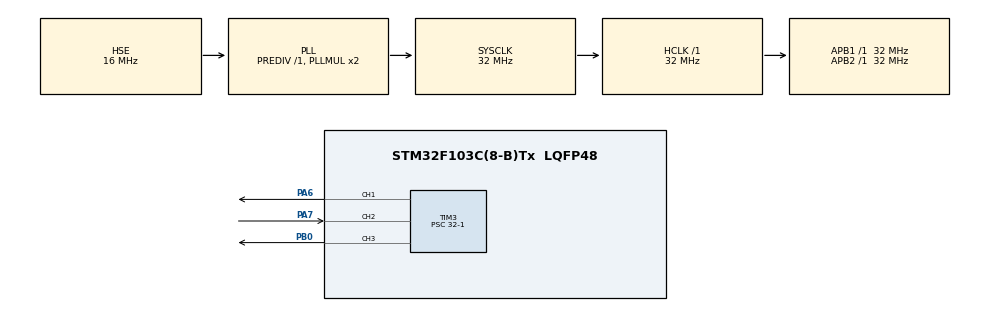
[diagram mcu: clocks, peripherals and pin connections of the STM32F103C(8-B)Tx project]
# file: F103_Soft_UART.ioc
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Mcu.Family=STM32F1
Mcu.Name=STM32F103C(8-B)Tx
Mcu.Package=LQFP48
NVIC.PriorityGroup=NVIC_PRIORITYGROUP_4
NVIC.TIM3_IRQn=true\:0\:0\:false\:false\:true\:true\:true\:true
PA6.GPIO_Speed=GPIO_SPEED_FREQ_HIGH
PA6.Signal=S_TIM3_CH1
PA7.GPIO_PuPd=GPIO_PULLUP
PA7.Signal=S_TIM3_CH2
PB0.Signal=S_TIM3_CH3
PD0-OSC_IN.Mode=HSE-External-Oscillator
PD0-OSC_IN.Signal=RCC_OSC_IN
PD1-OSC_OUT.Mode=HSE-External-Oscillator
PD1-OSC_OUT.Signal=RCC_OSC_OUT
ProjectManager.HeapSize=0x200
ProjectManager.StackSize=0x400
ProjectManager.TargetToolchain=STM32CubeIDE
RCC.AHBFreq_Value=32000000
RCC.APB1Freq_Value=32000000
RCC.APB1TimFreq_Value=32000000
RCC.APB2Freq_Value=32000000
RCC.APB2TimFreq_Value=32000000
RCC.HCLKFreq_Value=32000000
RCC.HSE_VALUE=16000000
RCC.PLLSourceVirtual=RCC_PLLSOURCE_HSE
RCC.SYSCLKFreq_VALUE=32000000
RCC.SYSCLKSource=RCC_SYSCLKSOURCE_PLLCLK
RCC.USBFreq_Value=32000000
SH.S_TIM3_CH1.0=TIM3_CH1,Output Compare1 CH1
SH.S_TIM3_CH2.0=TIM3_CH2,Input_Capture2_from_TI2
SH.S_TIM3_CH3.0=TIM3_CH3,Output Compare3 CH3
TIM3.Channel-Input_Capture2_from_TI2=TIM_CHANNEL_2
TIM3.Channel-Output\ Compare1\ CH1=TIM_CHANNEL_1
TIM3.Channel-Output\ Compare3\ CH3=TIM_CHANNEL_3
TIM3.ICPolarity_CH2=TIM_INPUTCHANNELPOLARITY_FALLING
TIM3.OCMode_1=TIM_OCMODE_FORCED_ACTIVE
TIM3.Prescaler=32-1
VP_TIM3_VS_ClockSourceINT.Mode=Internal
board=custom

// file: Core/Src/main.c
/* USER CODE BEGIN Header */
/**
  ******************************************************************************
  * @file           : main.c
  * @brief          : Main program body
  ******************************************************************************
  * @attention
  *
  * Copyright (c) 2024 STMicroelectronics.
  * All rights reserved.
  *
  * This software is licensed under terms that can be found in the LICENSE file
  * in the root directory of this software component.
  * If no LICENSE file comes with this software, it is provided AS-IS.
  *
  ******************************************************************************
  */
/* USER CODE END Header */
#include "main.h"

/* USER CODE BEGIN Includes */
#include "SoftwareSerial.h"
/* USER CODE END Includes */

TIM_HandleTypeDef htim3;

void SystemClock_Config(void);
static void MX_GPIO_Init(void);
static void MX_TIM3_Init(void);

/* USER CODE BEGIN 0 */
uint32_t check_if;
/* USER CODE END 0 */

int main(void)
{

  /* MCU Configuration--------------------------------------------------------*/

  /* Reset of all peripherals, Initializes the Flash interface and the Systick. */
  HAL_Init();

  /* Configure the system clock */
  SystemClock_Config();

  /* Initialize all configured peripherals */
  MX_GPIO_Init();
  MX_TIM3_Init();
  /* USER CODE BEGIN 2 */
  ssInit(9600); // Initialise software UART and specify the baud rate
  while(1) {
	  if(isRxAvailable()) {
		  ssWriteByte(ssReadByte());
		  check_if++;
	  }
  }

  /* USER CODE END 2 */

  /* Infinite loop */
  while (1)
  {

  }
}

void SystemClock_Config(void)
{
  RCC_OscInitTypeDef RCC_OscInitStruct = {0};
  RCC_ClkInitTypeDef RCC_ClkInitStruct = {0};

  /** Initializes the RCC Oscillators according to the specified parameters
  * in the RCC_OscInitTypeDef structure.
  */
  RCC_OscInitStruct.OscillatorType = RCC_OSCILLATORTYPE_HSE;
  RCC_OscInitStruct.HSEState = RCC_HSE_ON;
  RCC_OscInitStruct.HSEPredivValue = RCC_HSE_PREDIV_DIV1;
  RCC_OscInitStruct.HSIState = RCC_HSI_ON;
  RCC_OscInitStruct.PLL.PLLState = RCC_PLL_ON;
  RCC_OscInitStruct.PLL.PLLSource = RCC_PLLSOURCE_HSE;
  RCC_OscInitStruct.PLL.PLLMUL = RCC_PLL_MUL2;
  if (HAL_RCC_OscConfig(&RCC_OscInitStruct) != HAL_OK)
  {
    Error_Handler();
  }

  /** Initializes the CPU, AHB and APB buses clocks
  */
  RCC_ClkInitStruct.ClockType = RCC_CLOCKTYPE_HCLK|RCC_CLOCKTYPE_SYSCLK
                              |RCC_CLOCKTYPE_PCLK1|RCC_CLOCKTYPE_PCLK2;
  RCC_ClkInitStruct.SYSCLKSource = RCC_SYSCLKSOURCE_PLLCLK;
  RCC_ClkInitStruct.AHBCLKDivider = RCC_SYSCLK_DIV1;
  RCC_ClkInitStruct.APB1CLKDivider = RCC_HCLK_DIV1;
  RCC_ClkInitStruct.APB2CLKDivider = RCC_HCLK_DIV1;

  if (HAL_RCC_ClockConfig(&RCC_ClkInitStruct, FLASH_LATENCY_1) != HAL_OK)
  {
    Error_Handler();
  }
}

static void MX_TIM3_Init(void)
{

  TIM_ClockConfigTypeDef sClockSourceConfig = {0};
  TIM_MasterConfigTypeDef sMasterConfig = {0};
  TIM_OC_InitTypeDef sConfigOC = {0};
  TIM_IC_InitTypeDef sConfigIC = {0};

  htim3.Instance = TIM3;
  htim3.Init.Prescaler = 32-1;
  htim3.Init.CounterMode = TIM_COUNTERMODE_UP;
  htim3.Init.Period = 65535;
  htim3.Init.ClockDivision = TIM_CLOCKDIVISION_DIV1;
  htim3.Init.AutoReloadPreload = TIM_AUTORELOAD_PRELOAD_DISABLE;
  if (HAL_TIM_Base_Init(&htim3) != HAL_OK)
  {
    Error_Handler();
  }
  sClockSourceConfig.ClockSource = TIM_CLOCKSOURCE_INTERNAL;
  if (HAL_TIM_ConfigClockSource(&htim3, &sClockSourceConfig) != HAL_OK)
  {
    Error_Handler();
  }
  if (HAL_TIM_OC_Init(&htim3) != HAL_OK)
  {
    Error_Handler();
  }
  if (HAL_TIM_IC_Init(&htim3) != HAL_OK)
  {
    Error_Handler();
  }
  sMasterConfig.MasterOutputTrigger = TIM_TRGO_RESET;
  sMasterConfig.MasterSlaveMode = TIM_MASTERSLAVEMODE_DISABLE;
  if (HAL_TIMEx_MasterConfigSynchronization(&htim3, &sMasterConfig) != HAL_OK)
  {
    Error_Handler();
  }
  sConfigOC.OCMode = TIM_OCMODE_FORCED_ACTIVE;
  sConfigOC.Pulse = 0;
  sConfigOC.OCPolarity = TIM_OCPOLARITY_HIGH;
  sConfigOC.OCFastMode = TIM_OCFAST_DISABLE;
  if (HAL_TIM_OC_ConfigChannel(&htim3, &sConfigOC, TIM_CHANNEL_1) != HAL_OK)
  {
    Error_Handler();
  }
  sConfigIC.ICPolarity = TIM_INPUTCHANNELPOLARITY_FALLING;
  sConfigIC.ICSelection = TIM_ICSELECTION_DIRECTTI;
  sConfigIC.ICPrescaler = TIM_ICPSC_DIV1;
  sConfigIC.ICFilter = 0;
  if (HAL_TIM_IC_ConfigChannel(&htim3, &sConfigIC, TIM_CHANNEL_2) != HAL_OK)
  {
    Error_Handler();
  }
  sConfigOC.OCMode = TIM_OCMODE_TIMING;
  if (HAL_TIM_OC_ConfigChannel(&htim3, &sConfigOC, TIM_CHANNEL_3) != HAL_OK)
  {
    Error_Handler();
  }
  HAL_TIM_MspPostInit(&htim3);

}

static void MX_GPIO_Init(void)
{

  /* GPIO Ports Clock Enable */
  __HAL_RCC_GPIOD_CLK_ENABLE();
  __HAL_RCC_GPIOA_CLK_ENABLE();
  __HAL_RCC_GPIOB_CLK_ENABLE();

}

void Error_Handler(void)
{
  __disable_irq();
  while (1)
  {
  }
}
